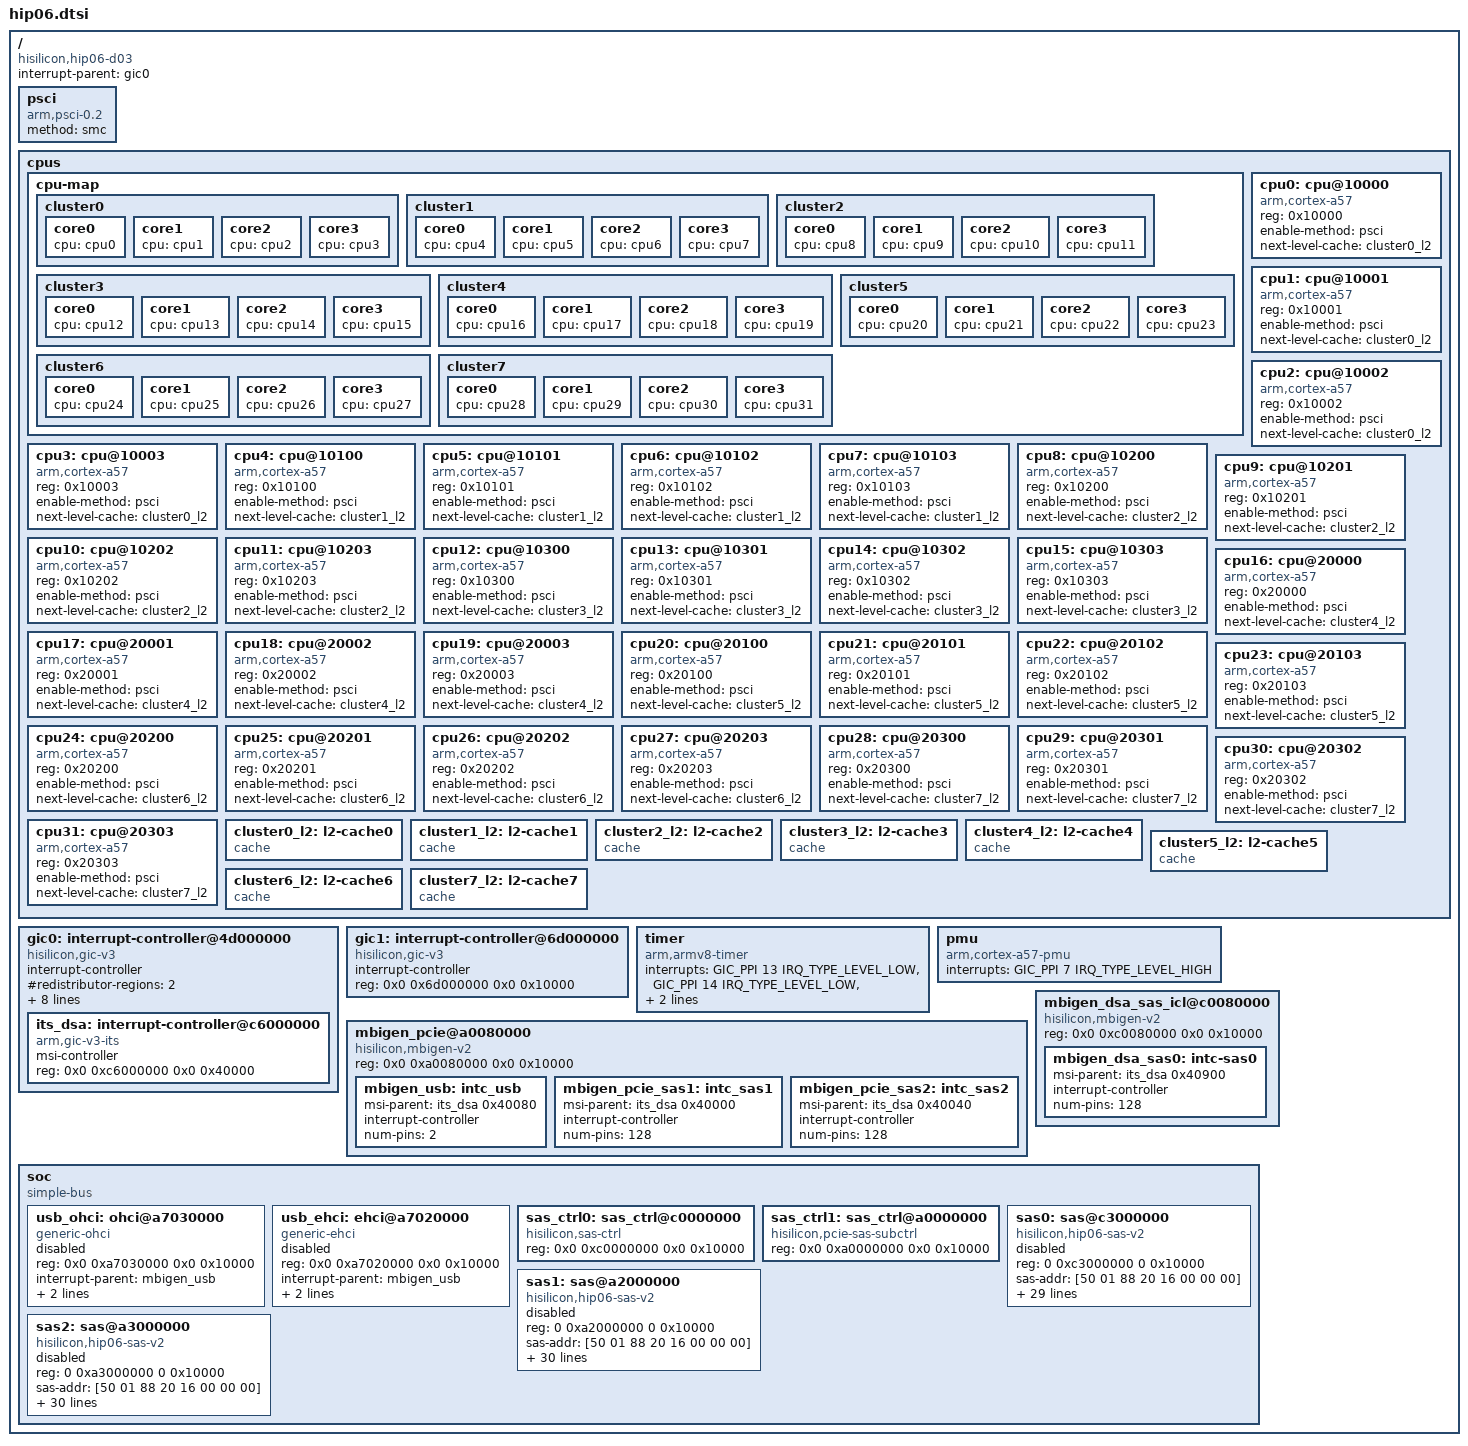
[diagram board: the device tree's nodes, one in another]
/**
 * dts file for Hisilicon D03 Development Board
 *
 * Copyright (C) 2016 Hisilicon Ltd.
 *
 * This program is free software; you can redistribute it and/or modify
 * it under the terms of the GNU General Public License version 2 as
 * publishhed by the Free Software Foundation.
 *
 */

#include <dt-bindings/interrupt-controller/arm-gic.h>

/ {
	compatible = "hisilicon,hip06-d03";
	interrupt-parent = <&gic0>;
	#address-cells = <2>;
	#size-cells = <2>;

	psci {
		compatible = "arm,psci-0.2";
		method = "smc";
	};

	cpus {
		#address-cells = <1>;
		#size-cells = <0>;

		cpu-map {
			cluster0 {
				core0 {
					cpu = <&cpu0>;
				};
				core1 {
					cpu = <&cpu1>;
				};
				core2 {
					cpu = <&cpu2>;
				};
				core3 {
					cpu = <&cpu3>;
				};
			};
			cluster1 {
				core0 {
					cpu = <&cpu4>;
				};
				core1 {
					cpu = <&cpu5>;
				};
				core2 {
					cpu = <&cpu6>;
				};
				core3 {
					cpu = <&cpu7>;
				};
			};
			cluster2 {
				core0 {
					cpu = <&cpu8>;
				};
				core1 {
					cpu = <&cpu9>;
				};
				core2 {
					cpu = <&cpu10>;
				};
				core3 {
					cpu = <&cpu11>;
				};
			};
			cluster3 {
				core0 {
					cpu = <&cpu12>;
				};
				core1 {
					cpu = <&cpu13>;
				};
				core2 {
					cpu = <&cpu14>;
				};
				core3 {
					cpu = <&cpu15>;
				};
			};
			cluster4 {
				core0 {
					cpu = <&cpu16>;
				};
				core1 {
					cpu = <&cpu17>;
				};
				core2 {
					cpu = <&cpu18>;
				};
				core3 {
					cpu = <&cpu19>;
				};
			};
			cluster5 {
				core0 {
					cpu = <&cpu20>;
				};
				core1 {
					cpu = <&cpu21>;
				};
				core2 {
					cpu = <&cpu22>;
				};
				core3 {
					cpu = <&cpu23>;
				};
			};
			cluster6 {
				core0 {
					cpu = <&cpu24>;
				};
				core1 {
					cpu = <&cpu25>;
				};
				core2 {
					cpu = <&cpu26>;
				};
				core3 {
					cpu = <&cpu27>;
				};
			};
			cluster7 {
				core0 {
					cpu = <&cpu28>;
				};
				core1 {
					cpu = <&cpu29>;
				};
				core2 {
					cpu = <&cpu30>;
				};
				core3 {
					cpu = <&cpu31>;
				};
			};
		};

		cpu0: cpu@10000 {
			device_type = "cpu";
			compatible = "arm,cortex-a57", "arm,armv8";
			reg = <0x10000>;
			enable-method = "psci";
			next-level-cache = <&cluster0_l2>;
		};

		cpu1: cpu@10001 {
			device_type = "cpu";
			compatible = "arm,cortex-a57", "arm,armv8";
			reg = <0x10001>;
			enable-method = "psci";
			next-level-cache = <&cluster0_l2>;
		};

		cpu2: cpu@10002 {
			device_type = "cpu";
			compatible = "arm,cortex-a57", "arm,armv8";
			reg = <0x10002>;
			enable-method = "psci";
			next-level-cache = <&cluster0_l2>;
		};

		cpu3: cpu@10003 {
			device_type = "cpu";
			compatible = "arm,cortex-a57", "arm,armv8";
			reg = <0x10003>;
			enable-method = "psci";
			next-level-cache = <&cluster0_l2>;
		};

		cpu4: cpu@10100 {
			device_type = "cpu";
			compatible = "arm,cortex-a57", "arm,armv8";
			reg = <0x10100>;
			enable-method = "psci";
			next-level-cache = <&cluster1_l2>;
		};

		cpu5: cpu@10101 {
			device_type = "cpu";
			compatible = "arm,cortex-a57", "arm,armv8";
			reg = <0x10101>;
			enable-method = "psci";
			next-level-cache = <&cluster1_l2>;
		};

		cpu6: cpu@10102 {
			device_type = "cpu";
			compatible = "arm,cortex-a57", "arm,armv8";
			reg = <0x10102>;
			enable-method = "psci";
			next-level-cache = <&cluster1_l2>;
		};

		cpu7: cpu@10103 {
			device_type = "cpu";
			compatible = "arm,cortex-a57", "arm,armv8";
			reg = <0x10103>;
			enable-method = "psci";
			next-level-cache = <&cluster1_l2>;
		};

		cpu8: cpu@10200 {
			device_type = "cpu";
			compatible = "arm,cortex-a57", "arm,armv8";
			reg = <0x10200>;
			enable-method = "psci";
			next-level-cache = <&cluster2_l2>;
		};

		cpu9: cpu@10201 {
			device_type = "cpu";
			compatible = "arm,cortex-a57", "arm,armv8";
			reg = <0x10201>;
			enable-method = "psci";
			next-level-cache = <&cluster2_l2>;
		};

		cpu10: cpu@10202 {
			device_type = "cpu";
			compatible = "arm,cortex-a57", "arm,armv8";
			reg = <0x10202>;
			enable-method = "psci";
			next-level-cache = <&cluster2_l2>;
		};

		cpu11: cpu@10203 {
			device_type = "cpu";
			compatible = "arm,cortex-a57", "arm,armv8";
			reg = <0x10203>;
			enable-method = "psci";
			next-level-cache = <&cluster2_l2>;
		};

		cpu12: cpu@10300 {
			device_type = "cpu";
			compatible = "arm,cortex-a57", "arm,armv8";
			reg = <0x10300>;
			enable-method = "psci";
			next-level-cache = <&cluster3_l2>;
		};

		cpu13: cpu@10301 {
			device_type = "cpu";
			compatible = "arm,cortex-a57", "arm,armv8";
			reg = <0x10301>;
			enable-method = "psci";
			next-level-cache = <&cluster3_l2>;
		};

		cpu14: cpu@10302 {
			device_type = "cpu";
			compatible = "arm,cortex-a57", "arm,armv8";
			reg = <0x10302>;
			enable-method = "psci";
			next-level-cache = <&cluster3_l2>;
		};

		cpu15: cpu@10303 {
			device_type = "cpu";
			compatible = "arm,cortex-a57", "arm,armv8";
			reg = <0x10303>;
			enable-method = "psci";
			next-level-cache = <&cluster3_l2>;
		};

		cpu16: cpu@20000 {
			device_type = "cpu";
			compatible = "arm,cortex-a57", "arm,armv8";
			reg = <0x20000>;
			enable-method = "psci";
			next-level-cache = <&cluster4_l2>;
		};

		cpu17: cpu@20001 {
			device_type = "cpu";
			compatible = "arm,cortex-a57", "arm,armv8";
			reg = <0x20001>;
			enable-method = "psci";
			next-level-cache = <&cluster4_l2>;
		};

		cpu18: cpu@20002 {
			device_type = "cpu";
			compatible = "arm,cortex-a57", "arm,armv8";
			reg = <0x20002>;
			enable-method = "psci";
			next-level-cache = <&cluster4_l2>;
		};

		cpu19: cpu@20003 {
			device_type = "cpu";
			compatible = "arm,cortex-a57", "arm,armv8";
			reg = <0x20003>;
			enable-method = "psci";
			next-level-cache = <&cluster4_l2>;
		};

		cpu20: cpu@20100 {
			device_type = "cpu";
			compatible = "arm,cortex-a57", "arm,armv8";
			reg = <0x20100>;
			enable-method = "psci";
			next-level-cache = <&cluster5_l2>;
		};

		cpu21: cpu@20101 {
			device_type = "cpu";
			compatible = "arm,cortex-a57", "arm,armv8";
			reg = <0x20101>;
			enable-method = "psci";
			next-level-cache = <&cluster5_l2>;
		};

		cpu22: cpu@20102 {
			device_type = "cpu";
			compatible = "arm,cortex-a57", "arm,armv8";
			reg = <0x20102>;
			enable-method = "psci";
			next-level-cache = <&cluster5_l2>;
		};

		cpu23: cpu@20103 {
			device_type = "cpu";
			compatible = "arm,cortex-a57", "arm,armv8";
			reg = <0x20103>;
			enable-method = "psci";
			next-level-cache = <&cluster5_l2>;
		};

		cpu24: cpu@20200 {
			device_type = "cpu";
			compatible = "arm,cortex-a57", "arm,armv8";
			reg = <0x20200>;
			enable-method = "psci";
			next-level-cache = <&cluster6_l2>;
		};

		cpu25: cpu@20201 {
			device_type = "cpu";
			compatible = "arm,cortex-a57", "arm,armv8";
			reg = <0x20201>;
			enable-method = "psci";
			next-level-cache = <&cluster6_l2>;
		};

		cpu26: cpu@20202 {
			device_type = "cpu";
			compatible = "arm,cortex-a57", "arm,armv8";
			reg = <0x20202>;
			enable-method = "psci";
			next-level-cache = <&cluster6_l2>;
		};

		cpu27: cpu@20203 {
			device_type = "cpu";
			compatible = "arm,cortex-a57", "arm,armv8";
			reg = <0x20203>;
			enable-method = "psci";
			next-level-cache = <&cluster6_l2>;
		};

		cpu28: cpu@20300 {
			device_type = "cpu";
			compatible = "arm,cortex-a57", "arm,armv8";
			reg = <0x20300>;
			enable-method = "psci";
			next-level-cache = <&cluster7_l2>;
		};

		cpu29: cpu@20301 {
			device_type = "cpu";
			compatible = "arm,cortex-a57", "arm,armv8";
			reg = <0x20301>;
			enable-method = "psci";
			next-level-cache = <&cluster7_l2>;
		};

		cpu30: cpu@20302 {
			device_type = "cpu";
			compatible = "arm,cortex-a57", "arm,armv8";
			reg = <0x20302>;
			enable-method = "psci";
			next-level-cache = <&cluster7_l2>;
		};

		cpu31: cpu@20303 {
			device_type = "cpu";
			compatible = "arm,cortex-a57", "arm,armv8";
			reg = <0x20303>;
			enable-method = "psci";
			next-level-cache = <&cluster7_l2>;
		};

		cluster0_l2: l2-cache0 {
			compatible = "cache";
		};

		cluster1_l2: l2-cache1 {
			compatible = "cache";
		};

		cluster2_l2: l2-cache2 {
			compatible = "cache";
		};

		cluster3_l2: l2-cache3 {
			compatible = "cache";
		};

		cluster4_l2: l2-cache4 {
			compatible = "cache";
		};

		cluster5_l2: l2-cache5 {
			compatible = "cache";
		};

		cluster6_l2: l2-cache6 {
			compatible = "cache";
		};

		cluster7_l2: l2-cache7 {
			compatible = "cache";
		};
	};

	gic0: interrupt-controller@4d000000 {
		compatible = "hisilicon,gic-v3";
		#interrupt-cells = <3>;
		#address-cells = <2>;
		#size-cells = <2>;
		ranges;
		interrupt-controller;
		#redistributor-regions = <2>;
		redistributor-stride = <0x0 0x30000>;
		reg = <0x0 0x4d000000 0 0x10000>,	/* GICD A*/
		      <0x0 0x4d100000 0 0x300000>,	/* GICR A*/
		      <0x0 0x6d100000 0 0x300000>,	/* GICR C*/
		      <0x0 0xfe000000 0 0x10000>,	/* GICC */
		      <0x0 0xfe010000 0 0x10000>,       /* GICH */
		      <0x0 0xfe020000 0 0x10000>;       /* GICV */
		interrupts = <GIC_PPI 9 IRQ_TYPE_LEVEL_HIGH>;

		its_dsa: interrupt-controller@c6000000 {
			compatible = "arm,gic-v3-its";
			msi-controller;
			#msi-cells = <1>;
			reg = <0x0 0xc6000000 0x0 0x40000>;
		};
	};

	gic1: interrupt-controller@6d000000 {
		compatible = "hisilicon,gic-v3";
		#interrupt-cells = <3>;
		#address-cells = <2>;
		#size-cells = <2>;
		interrupt-controller;
		reg = <0x0 0x6d000000 0x0 0x10000>;
	};

	timer {
		compatible = "arm,armv8-timer";
		interrupts = <GIC_PPI 13 IRQ_TYPE_LEVEL_LOW>,
			     <GIC_PPI 14 IRQ_TYPE_LEVEL_LOW>,
			     <GIC_PPI 11 IRQ_TYPE_LEVEL_LOW>,
			     <GIC_PPI 10 IRQ_TYPE_LEVEL_LOW>;
	};

	pmu {
		compatible = "arm,cortex-a57-pmu";
		interrupts = <GIC_PPI 7 IRQ_TYPE_LEVEL_HIGH>;
	};

	mbigen_pcie@a0080000 {
		compatible = "hisilicon,mbigen-v2";
		reg = <0x0 0xa0080000 0x0 0x10000>;

		mbigen_usb: intc_usb {
			msi-parent = <&its_dsa 0x40080>;
			interrupt-controller;
			#interrupt-cells = <2>;
			num-pins = <2>;
		};

		mbigen_pcie_sas1: intc_sas1 {
			msi-parent = <&its_dsa 0x40000>;
			interrupt-controller;
			#interrupt-cells = <2>;
			num-pins = <128>;
		};

		mbigen_pcie_sas2: intc_sas2 {
			msi-parent = <&its_dsa 0x40040>;
			interrupt-controller;
			#interrupt-cells = <2>;
			num-pins = <128>;
		};

	};

	mbigen_dsa_sas_icl@c0080000 {
		compatible = "hisilicon,mbigen-v2";
		reg = <0x0 0xc0080000 0x0 0x10000>;

		mbigen_dsa_sas0: intc-sas0 {
			msi-parent = <&its_dsa 0x40900>;
			interrupt-controller;
			#interrupt-cells = <2>;
			num-pins = <128>;
		};
	};

	soc {
		compatible = "simple-bus";
		#address-cells = <2>;
		#size-cells = <2>;
		ranges;

		usb_ohci: ohci@a7030000 {
			compatible = "generic-ohci";
			reg = <0x0 0xa7030000 0x0 0x10000>;
			interrupt-parent = <&mbigen_usb>;
			interrupts = <64 4>;
			dma-coherent;
			status = "disabled";
		};

		usb_ehci: ehci@a7020000 {
			compatible = "generic-ehci";
			reg = <0x0 0xa7020000 0x0 0x10000>;
			interrupt-parent = <&mbigen_usb>;
			interrupts = <65 4>;
			dma-coherent;
			status = "disabled";
		};

		sas_ctrl0: sas_ctrl@c0000000 {
			compatible = "hisilicon,sas-ctrl", "syscon";
			reg = <0x0 0xc0000000 0x0 0x10000>;
		};

		sas_ctrl1: sas_ctrl@a0000000 {
			compatible = "hisilicon,pcie-sas-subctrl", "syscon";
			reg = <0x0 0xa0000000 0x0 0x10000>;
		};

		sas0: sas@c3000000 {
			compatible = "hisilicon,hip06-sas-v2";
			reg = <0 0xc3000000 0 0x10000>;
			sas-addr = [50 01 88 20 16 00 00 00];
			hisilicon,sas-syscon = <&sas_ctrl0>;
			ctrl-reset-reg = <0xa60>;
			ctrl-reset-sts-reg = <0x5a30>;
			ctrl-clock-ena-reg = <0x338>;
			queue-count = <16>;
			phy-count = <8>;
			dma-coherent;
			interrupt-parent = <&mbigen_dsa_sas0>;
			interrupts = <64 4>,<65 4>,<66 4>,<67 4>,<68 4>,
					<69 4>,<70 4>,<71 4>,<72 4>,<73 4>,
					<75 4>,<76 4>,<77 4>,<78 4>,<79 4>,
					<80 4>,<81 4>,<82 4>,<83 4>,<84 4>,
					<85 4>,<86 4>,<87 4>,<88 4>,<89 4>,
					<90 4>,<91 4>,<92 4>,<93 4>,<94 4>,
					<95 4>,<96 4>,<97 4>,<98 4>,<99 4>,
					<100 4>,<101 4>,<102 4>,<103 4>,<104 4>,
					<105 4>,<106 4>,<107 4>,<108 4>,<109 4>,
					<110 4>,<111 4>,<112 4>,<113 4>,<114 4>,
					<115 4>,<116 4>,<117 4>,<118 4>,<119 4>,
					<120 4>,<121 4>,<122 4>,<123 4>,<124 4>,
					<125 4>,<126 4>,<127 4>,<128 4>,<129 4>,
					<130 4>,<131 4>,<132 4>,<133 4>,<134 4>,
					<135 4>,<136 4>,<137 4>,<138 4>,<139 4>,
					<140 4>,<141 4>,<142 4>,<143 4>,<144 4>,
					<145 4>,<146 4>,<147 4>,<148 4>,<149 4>,
					<150 4>,<151 4>,<152 4>,<153 4>,<154 4>,
					<155 4>,<156 4>,<157 4>,<158 4>,<159 4>,
					<160 4>,<601 1>,<602 1>,<603 1>,<604 1>,
					<605 1>,<606 1>,<607 1>,<608 1>,<609 1>,
					<610 1>,<611 1>,<612 1>,<613 1>,<614 1>,
					<615 1>,<616 1>,<617 1>,<618 1>,<619 1>,
					<620 1>,<621 1>,<622 1>,<623 1>,<624 1>,
					<625 1>,<626 1>,<627 1>,<628 1>,<629 1>,
					<630 1>,<631 1>,<632 1>;
			status = "disabled";
		};

		sas1: sas@a2000000 {
			compatible = "hisilicon,hip06-sas-v2";
			reg = <0 0xa2000000 0 0x10000>;
			sas-addr = [50 01 88 20 16 00 00 00];
			hisilicon,sas-syscon = <&sas_ctrl1>;
			am-max-trans;
			ctrl-reset-reg = <0xa18>;
			ctrl-reset-sts-reg = <0x5a0c>;
			ctrl-clock-ena-reg = <0x318>;
			queue-count = <16>;
			phy-count = <8>;
			dma-coherent;
			interrupt-parent = <&mbigen_pcie_sas1>;
			interrupts = <64 4>,<65 4>,<66 4>,<67 4>,<68 4>,
					<69 4>,<70 4>,<71 4>,<72 4>,<73 4>,
					<74 4>,<75 4>,<76 4>,<77 4>,<78 4>,
					<79 4>,<80 4>,<81 4>,<82 4>,<83 4>,
					<84 4>,<85 4>,<86 4>,<87 4>,<88 4>,
					<89 4>,<90 4>,<91 4>,<92 4>,<93 4>,
					<94 4>,<95 4>,<96 4>,<97 4>,<98 4>,
					<99 4>,<100 4>,<101 4>,<102 4>,<103 4>,
					<104 4>,<105 4>,<106 4>,<107 4>,<108 4>,
					<109 4>,<110 4>,<111 4>,<112 4>,<113 4>,
					<114 4>,<115 4>,<116 4>,<117 4>,<118 4>,
					<119 4>,<120 4>,<121 4>,<122 4>,<123 4>,
					<124 4>,<125 4>,<126 4>,<127 4>,<128 4>,
					<129 4>,<130 4>,<131 4>,<132 4>,<133 4>,
					<134 4>,<135 4>,<136 4>,<137 4>,<138 4>,
					<139 4>,<140 4>,<141 4>,<142 4>,<143 4>,
					<144 4>,<145 4>,<146 4>,<147 4>,<148 4>,
					<149 4>,<150 4>,<151 4>,<152 4>,<153 4>,
					<154 4>,<155 4>,<156 4>,<157 4>,<158 4>,
					<159 4>,<576 1>,<577 1>,<578 1>,<579 1>,
					<580 1>,<581 1>,<582 1>,<583 1>,<584 1>,
					<585 1>,<586 1>,<587 1>,<588 1>,<589 1>,
					<590 1>,<591 1>,<592 1>,<593 1>,<594 1>,
					<595 1>,<596 1>,<597 1>,<598 1>,<599 1>,
					<600 1>,<601 1>,<602 1>,<603 1>,<604 1>,
					<605 1>,<606 1>,<607 1>;
			status = "disabled";
		};

		sas2: sas@a3000000 {
			compatible = "hisilicon,hip06-sas-v2";
			reg = <0 0xa3000000 0 0x10000>;
			sas-addr = [50 01 88 20 16 00 00 00];
			hisilicon,sas-syscon = <&sas_ctrl1>;
			ctrl-reset-reg = <0xae0>;
			ctrl-reset-sts-reg = <0x5a70>;
			ctrl-clock-ena-reg = <0x3a8>;
			queue-count = <16>;
			phy-count = <8>;
			dma-coherent;
			interrupt-parent = <&mbigen_pcie_sas2>;
			interrupts = <192 4>,<193 4>,<194 4>,<195 4>,<196 4>,
					<197 4>,<198 4>,<199 4>,<200 4>,<201 4>,
					<202 4>,<203 4>,<204 4>,<205 4>,<206 4>,
					<207 4>,<208 4>,<209 4>,<210 4>,<211 4>,
					<212 4>,<213 4>,<214 4>,<215 4>,<216 4>,
					<217 4>,<218 4>,<219 4>,<220 4>,<221 4>,
					<222 4>,<223 4>,<224 4>,<225 4>,<226 4>,
					<227 4>,<228 4>,<229 4>,<230 4>,<231 4>,
					<232 4>,<233 4>,<234 4>,<235 4>,<236 4>,
					<237 4>,<238 4>,<239 4>,<240 4>,<241 4>,
					<242 4>,<243 4>,<244 4>,<245 4>,<246 4>,
					<247 4>,<248 4>,<249 4>,<250 4>,<251 4>,
					<252 4>,<253 4>,<254 4>,<255 4>,<256 4>,
					<257 4>,<258 4>,<259 4>,<260 4>,<261 4>,
					<262 4>,<263 4>,<264 4>,<265 4>,<266 4>,
					<267 4>,<268 4>,<269 4>,<270 4>,<271 4>,
					<272 4>,<273 4>,<274 4>,<275 4>,<276 4>,
					<277 4>,<278 4>,<279 4>,<280 4>,<281 4>,
					<282 4>,<283 4>,<284 4>,<285 4>,<286 4>,
					<287 4>,<608 1>,<609 1>,<610 1>,<611 1>,
					<612 1>,<613 1>,<614 1>,<615 1>,<616 1>,
					<617 1>,<618 1>,<619 1>,<620 1>,<621 1>,
					<622 1>,<623 1>,<624 1>,<625 1>,<626 1>,
					<627 1>,<628 1>,<629 1>,<630 1>,<631 1>,
					<632 1>,<633 1>,<634 1>,<635 1>,<636 1>,
					<637 1>,<638 1>,<639 1>;
			status = "disabled";
		};


	};

};
